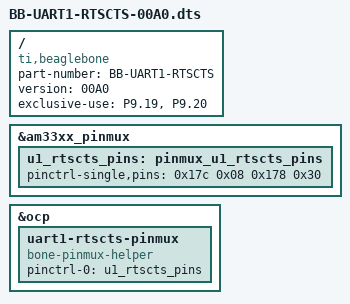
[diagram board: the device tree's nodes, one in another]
/*
 * Copyright 2018
 * Yantrr Electronic Systems Pvt. Ltd. - http://www.yantrr.com/
 *
 * BeagleBone cape RS485 / RS422 using UART1-RTSCTS connector pins P9.19 P9.20
 *
 * This program is free software: you can redistribute it and/or modify
 * it under the terms of the GNU General Public License as published by
 * the Free Software Foundation, either version 3 of the License, or 
 * (at your option) any later version.
 *
 * This program is distributed in the hope that it will be useful,
 * but WITHOUT ANY WARRANTY; without even the implied warranty of
 * MERCHANTABILITY or FITNESS FOR A PARTICULAR PURPOSE.  See the
 * GNU General Public License for more details.
 *
*/

/dts-v1/;
/plugin/;

/{
  compatible = "ti,beaglebone", "ti,beaglebone-black";

  part-number = "BB-UART1-RTSCTS";
  version = "00A0";

  exclusive-use =
    "P9.19",    // uart1_rtsn     conflict with I2C2_SCL  i.e. cape EEPROM
    "P9.20";    // uart1_ctsn     conflict with I2C2_SDA  i.e. cape EEPROM

  fragment@0 {
    /* Sets pinmux for flow control pins. */
    target = <&am33xx_pinmux>;
    __overlay__ {
      u1_rtscts_pins: pinmux_u1_rtscts_pins {
        pinctrl-single,pins = <
          0x17c 0x08      /* mode 0 (uart1_rtsn) */
          0x178 0x30      /* mode 0 (uart1_ctsn) */
        >;
      };
    };
  };

  fragment@1 {
    /* Enable pinmux-helper driver for setting mux configuration. */
    target = <&ocp>; /* On-Chip Peripherals */
    __overlay__ {
      uart1-rtscts-pinmux {
        compatible = "bone-pinmux-helper"; /* Use the pinmux helper */
        status="okay";
        /* Define custom names for indexes in pinctrl array: */
        pinctrl-names = "default";
        /* Set the elements of the pinctrl array to the pinmux overlays
           defined above: */
        pinctrl-0 = <&u1_rtscts_pins>;
      };
    };
  };
};
